# DSS_DSI_DSI_30270000h register map
Vendor: Texas Instruments
Peripheral module from a debugger description file (folder am62L).
Registers are 32-bit, read-only, reset 0x0 unless marked. A register's access mark holds for its fields unless they carry their own. Offsets are as the file gives them; lines under a group give offsets from that group; [hi:lo] are bit positions; {n}, {i} and the like mark numbered series; 'fields as' and 'values as' point back to an identical list; <NAME> marks a mode.

## dsi
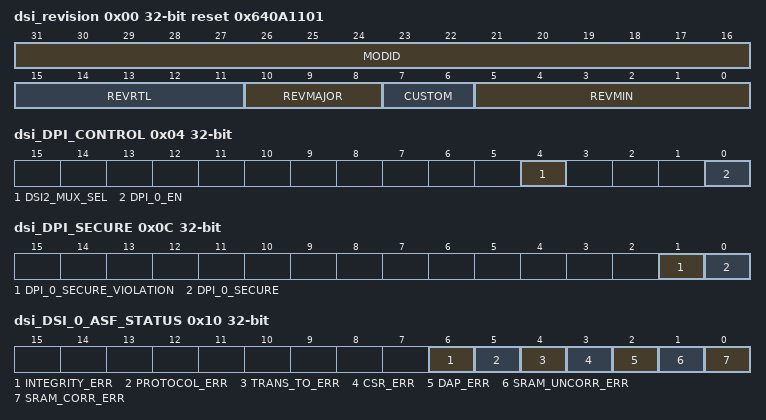
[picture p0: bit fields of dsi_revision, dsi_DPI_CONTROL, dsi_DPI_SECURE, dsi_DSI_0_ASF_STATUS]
0x00 dsi_revision reset 0x640A1101 — The REVISION register contains the DSI revision number and PID
  [31:16] MODID — Module ID Field Reset Source: rstn
  [15:11] REVRTL — RTL Revision Reset Source: rstn
  [10:8] REVMAJOR — Major Revision Reset Source: rstn
  [7:6] CUSTOM — Custom Reset Source: rstn
  [5:0] REVMIN — Minor Revision Reset Source: rstn
0x04 dsi_DPI_CONTROL rw — Controls the DPI Video Input ports of the DSI Wrapper
  [4] DSI2_MUX_SEL — Select between DPI-1 and DPI-2 to drive the DPI input of DSITX2 0 DPI-1 is selected1 DPI-2 is selected
  [0] DPI_0_EN — Enable for DPI-0 input 0 DPI-0 is disabled1 DPI-0 is enabled
0x08 dsi_DSC_CONTROL access not given reset not defined — Controls the DSC Encoder for DSI
0x0C dsi_DPI_SECURE access not given — Controls the DPI Video Input ports SECURE settings
  [1] DPI_0_SECURE_VIOLATION — SECURE VIOLATION status for DPI-0 input. Write-1 to clear the status 0 DPI-0 secure settings are ok1 DPI-0 secure settings are not ok, data is discarded (access R/W1TC)
  [0] DPI_0_SECURE rw — SECURE bit for DPI-0 input 0 DPI-0 is non-secure1 DPI-0 is secure
0x10 dsi_DSI_0_ASF_STATUS — ASF Status
  [6] INTEGRITY_ERR — INTEGRITY_ERR Reset Source: rstn
  [5] PROTOCOL_ERR — PROTOCOL_ERR Reset Source: rstn
  [4] TRANS_TO_ERR — TRANS_TO_ERR Reset Source: rstn
  [3] CSR_ERR — CSR_ERR Reset Source: rstn
  [2] DAP_ERR — DAP_ERR Reset Source: rstn
  [1] SRAM_UNCORR_ERR — SRAM_UNCORR_ERR Reset Source: rstn
  [0] SRAM_CORR_ERR — SRAM_CORR_ERR Reset Source: rstn
